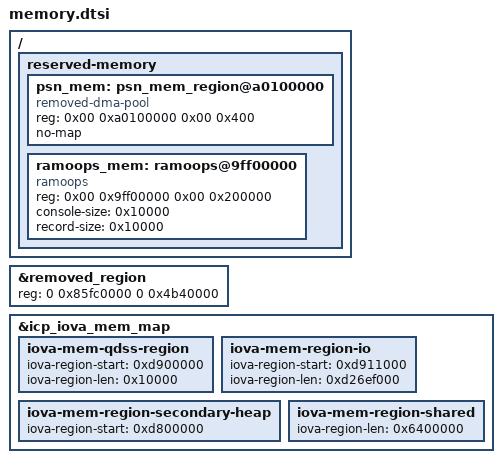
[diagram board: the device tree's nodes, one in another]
/*
 * Copyright (c) 2024, MeizuCustoms enthusiasts
 *
 * This program is free software; you can redistribute it and/or modify
 * it under the terms of the GNU General Public License version 2 and
 * only version 2 as published by the Free Software Foundation.
 *
 * This program is distributed in the hope that it will be useful,
 * but WITHOUT ANY WARRANTY; without even the implied warranty of
 * MERCHANTABILITY or FITNESS FOR A PARTICULAR PURPOSE.  See the
 * GNU General Public License for more details.
 */

/ {
    reserved-memory {
        psn_mem: psn_mem_region@a0100000 {
			compatible = "removed-dma-pool";
			reg = <0x00 0xa0100000 0x00 0x400>;
            no-map;
		};

        ramoops_mem: ramoops@9ff00000 {
			compatible = "ramoops";
            reg = <0x00 0x9ff00000 0x00 0x200000>;
			console-size = <0x10000>;
			record-size = <0x10000>;
		};
    };
};

&removed_region {
    reg = <0 0x85fc0000 0 0x4b40000>;
};

&icp_iova_mem_map {
	iova-mem-qdss-region {
		iova-region-start = <0xd900000>;
		iova-region-len = <0x10000>;
	};

	iova-mem-region-io {
		iova-region-start = <0xd911000>;
		iova-region-len = <0xd26ef000>;
	};

	iova-mem-region-secondary-heap {
		iova-region-start = <0xd800000>;
	};

	iova-mem-region-shared {
		iova-region-len = <0x6400000>;
	};
};
